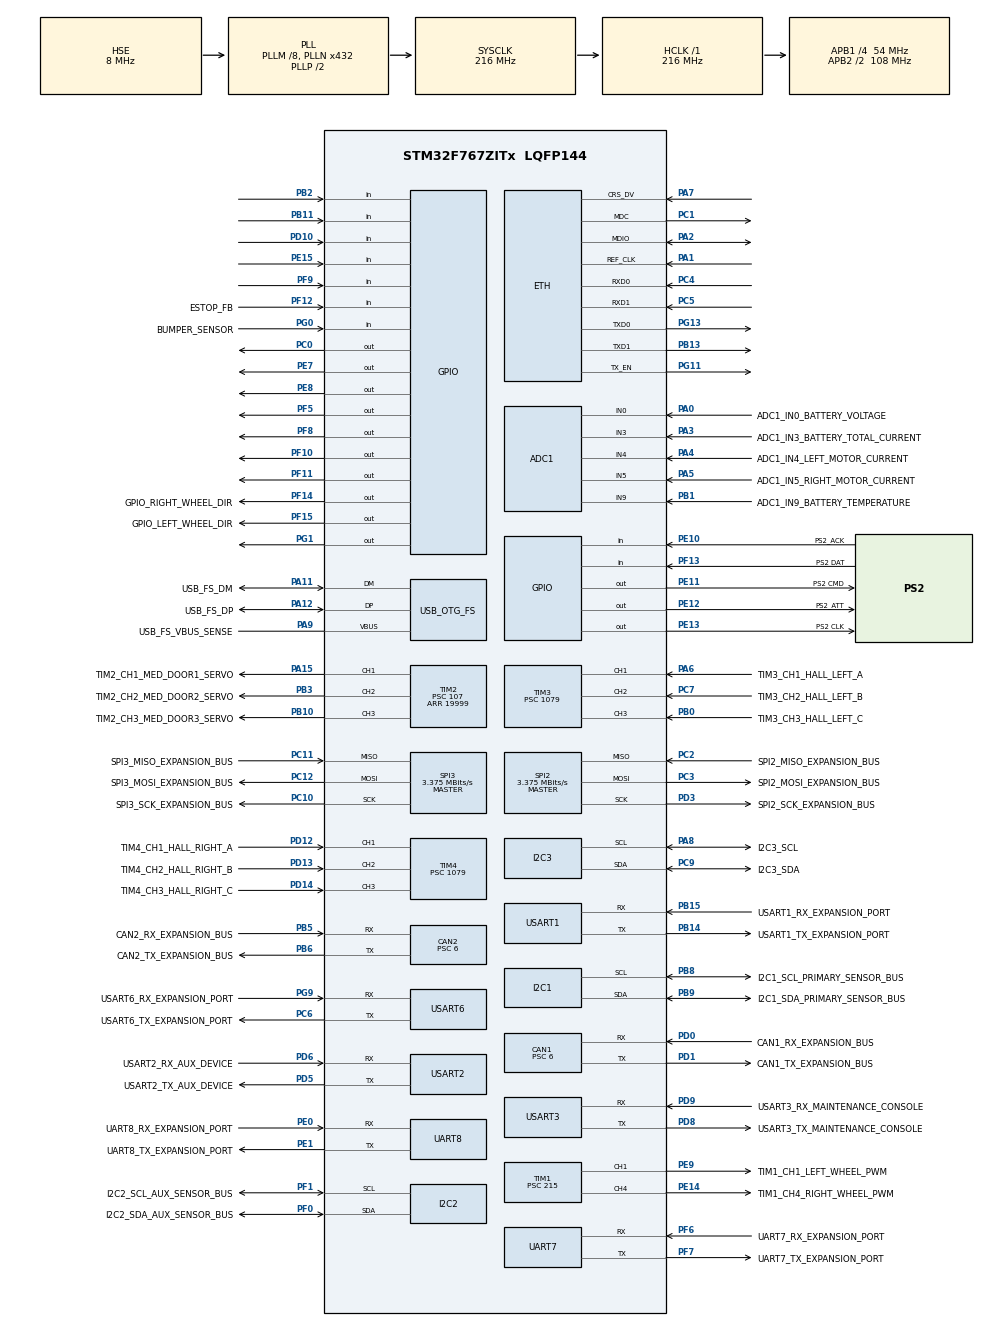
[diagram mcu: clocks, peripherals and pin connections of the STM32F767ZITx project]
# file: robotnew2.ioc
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ADC1.Channel-0\#ChannelRegularConversion=ADC_CHANNEL_0
ADC1.Channel-1\#ChannelRegularConversion=ADC_CHANNEL_3
ADC1.Channel-2\#ChannelRegularConversion=ADC_CHANNEL_4
ADC1.Channel-3\#ChannelRegularConversion=ADC_CHANNEL_5
ADC1.Channel-4\#ChannelRegularConversion=ADC_CHANNEL_9
ADC1.ContinuousConvMode=ENABLE
ADC1.DMAContinuousRequests=ENABLE
ADC1.NbrOfConversion=5
ADC1.NbrOfConversionFlag=1
ADC1.Rank-0\#ChannelRegularConversion=1
ADC1.Rank-1\#ChannelRegularConversion=2
ADC1.Rank-2\#ChannelRegularConversion=3
ADC1.Rank-3\#ChannelRegularConversion=4
ADC1.Rank-4\#ChannelRegularConversion=5
ADC1.SamplingTime-0\#ChannelRegularConversion=ADC_SAMPLETIME_480CYCLES
ADC1.SamplingTime-1\#ChannelRegularConversion=ADC_SAMPLETIME_480CYCLES
ADC1.SamplingTime-2\#ChannelRegularConversion=ADC_SAMPLETIME_480CYCLES
ADC1.SamplingTime-3\#ChannelRegularConversion=ADC_SAMPLETIME_480CYCLES
ADC1.SamplingTime-4\#ChannelRegularConversion=ADC_SAMPLETIME_480CYCLES
ADC1.ScanConvMode=ADC_SCAN_ENABLE
ADC1.master=1
CAN1.BS1=CAN_BS1_15TQ
CAN1.BS2=CAN_BS2_2TQ
CAN1.CalculateBaudRate=500000
CAN1.CalculateTimeBit=2000
CAN1.CalculateTimeQuantum=111.11111111111111
CAN1.NART=ENABLE
CAN1.Prescaler=6
CAN2.BS1=CAN_BS1_15TQ
CAN2.BS2=CAN_BS2_2TQ
CAN2.CalculateBaudRate=500000
CAN2.CalculateTimeBit=2000
CAN2.CalculateTimeQuantum=111.11111111111111
CAN2.Prescaler=6
CORTEX_M7.CPU_ICache=Enabled
CORTEX_M7.Enable-Cortex_Memory_Protection_Unit_Region0_Settings=__NULL
CORTEX_M7.MPU_Control=__NULL
CORTEX_M7.default_mode_Activation=0
Dma.ADC1.0.Direction=DMA_PERIPH_TO_MEMORY
Dma.ADC1.0.FIFOMode=DMA_FIFOMODE_DISABLE
Dma.ADC1.0.Instance=DMA2_Stream0
Dma.ADC1.0.MemDataAlignment=DMA_MDATAALIGN_HALFWORD
Dma.ADC1.0.MemInc=DMA_MINC_ENABLE
Dma.ADC1.0.Mode=DMA_CIRCULAR
Dma.ADC1.0.PeriphDataAlignment=DMA_PDATAALIGN_HALFWORD
Dma.ADC1.0.PeriphInc=DMA_PINC_DISABLE
Dma.ADC1.0.Priority=DMA_PRIORITY_LOW
Dma.Request0=ADC1
ETH.MediaInterface=HAL_ETH_RMII_MODE
FREERTOS.Tasks01=defaultTask,0,256,StartDefaultTask,Default,NULL,Dynamic,NULL,NULL
FREERTOS.configTOTAL_HEAP_SIZE=81920
FREERTOS.configUSE_NEWLIB_REENTRANT=1
I2C1.Timing=0x20404768
I2C2.Timing=0x20404768
I2C3.Timing=0x20404768
LWIP.BSP.number=1
LWIP.IP_ADDRESS=192.168.001.067
LWIP.LWIP_DHCP=0
LWIP.MEMP_NUM_UDP_PCB=15
LWIP.MEM_SIZE=10240
LWIP.NETMASK_ADDRESS=255.255.255.000
LWIP.PBUF_POOL_BUFSIZE=1536
LWIP.Version=v2.1.2_Cube
LWIP0.BSP.STBoard=false
LWIP0.BSP.api=BSP_COMPONENT_DRIVER
LWIP0.BSP.component=LAN8742
LWIP0.BSP.instance=LAN8742
LWIP0.BSP.name=Driver_PHY
LWIP0.BSP.semaphore=S_LAN8742
LWIP0.BSP.solution=LAN8742
Mcu.Family=STM32F7
Mcu.Name=STM32F767ZITx
Mcu.Package=LQFP144
NVIC.CAN1_RX0_IRQn=true\:5\:0\:true\:false\:true\:false\:true\:true\:true
NVIC.CAN1_SCE_IRQn=true\:5\:0\:true\:false\:true\:false\:true\:true\:true
NVIC.CAN1_TX_IRQn=true\:5\:0\:true\:false\:true\:false\:true\:true\:true
NVIC.CAN2_RX0_IRQn=true\:5\:0\:true\:false\:true\:false\:true\:true\:true
NVIC.CAN2_SCE_IRQn=true\:5\:0\:true\:false\:true\:false\:true\:true\:true
NVIC.CAN2_TX_IRQn=true\:5\:0\:true\:false\:true\:false\:true\:true\:true
NVIC.DMA2_Stream0_IRQn=true\:5\:0\:true\:false\:true\:false\:false\:true\:true
NVIC.ETH_IRQn=true\:5\:0\:false\:false\:true\:true\:false\:true\:true
NVIC.I2C1_ER_IRQn=true\:5\:0\:true\:false\:true\:false\:true\:true\:true
NVIC.I2C1_EV_IRQn=true\:5\:0\:true\:false\:true\:false\:true\:true\:true
NVIC.I2C2_ER_IRQn=true\:5\:0\:true\:false\:true\:false\:true\:true\:true
NVIC.I2C2_EV_IRQn=true\:5\:0\:true\:false\:true\:false\:true\:true\:true
NVIC.I2C3_ER_IRQn=true\:5\:0\:true\:false\:true\:false\:true\:true\:true
NVIC.I2C3_EV_IRQn=true\:5\:0\:true\:false\:true\:false\:true\:true\:true
NVIC.OTG_FS_IRQn=true\:5\:0\:false\:false\:true\:true\:false\:true\:true
NVIC.PriorityGroup=NVIC_PRIORITYGROUP_4
NVIC.SPI2_IRQn=true\:5\:0\:true\:false\:true\:false\:true\:true\:true
NVIC.SPI3_IRQn=true\:5\:0\:true\:false\:true\:false\:true\:true\:true
NVIC.TIM3_IRQn=true\:5\:0\:true\:false\:true\:false\:true\:true\:true
NVIC.TIM4_IRQn=true\:5\:0\:true\:false\:true\:false\:true\:true\:true
NVIC.TIM6_DAC_IRQn=true\:15\:0\:false\:false\:true\:false\:false\:true\:true
NVIC.TimeBase=TIM6_DAC_IRQn
NVIC.TimeBaseIP=TIM6
NVIC.UART7_IRQn=true\:5\:0\:false\:false\:true\:true\:true\:true\:true
NVIC.UART8_IRQn=true\:5\:0\:false\:false\:true\:true\:true\:true\:true
NVIC.USART1_IRQn=true\:5\:0\:false\:false\:true\:true\:true\:true\:true
NVIC.USART2_IRQn=true\:5\:0\:true\:false\:true\:false\:true\:true\:true
NVIC.USART3_IRQn=true\:5\:0\:true\:false\:true\:false\:true\:true\:true
NVIC.USART6_IRQn=true\:5\:0\:true\:false\:true\:false\:true\:true\:true
PA0/WKUP.GPIO_Label=ADC1_IN0_BATTERY_VOLTAGE
PA0/WKUP.Signal=ADCx_IN0
PA1.Mode=RMII
PA1.Signal=ETH_REF_CLK
PA11.GPIO_Label=USB_FS_DM
PA11.Mode=Device_Only
PA11.Signal=USB_OTG_FS_DM
PA12.GPIO_Label=USB_FS_DP
PA12.Mode=Device_Only
PA12.Signal=USB_OTG_FS_DP
PA13.Mode=Serial_Wire
PA13.Signal=SYS_JTMS-SWDIO
PA14.Mode=Serial_Wire
PA14.Signal=SYS_JTCK-SWCLK
PA15.GPIO_Label=TIM2_CH1_MED_DOOR1_SERVO
PA15.Signal=S_TIM2_CH1_ETR
PA2.Mode=RMII
PA2.Signal=ETH_MDIO
PA3.GPIO_Label=ADC1_IN3_BATTERY_TOTAL_CURRENT
PA3.Signal=ADCx_IN3
PA4.GPIO_Label=ADC1_IN4_LEFT_MOTOR_CURRENT
PA4.Signal=ADCx_IN4
PA5.GPIO_Label=ADC1_IN5_RIGHT_MOTOR_CURRENT
PA5.Signal=ADCx_IN5
PA6.GPIO_Label=TIM3_CH1_HALL_LEFT_A
PA6.Signal=S_TIM3_CH1
PA7.Mode=RMII
PA7.Signal=ETH_CRS_DV
PA8.GPIO_Label=I2C3_SCL
PA8.GPIO_Mode=GPIO_MODE_AF_OD
PA8.GPIO_Pu=GPIO_NOPULL
PA8.GPIO_Speed=GPIO_SPEED_FREQ_VERY_HIGH
PA8.Mode=I2C
PA8.Signal=I2C3_SCL
PA9.GPIO_Label=USB_FS_VBUS_SENSE
PA9.Mode=Activate_VBUS
PA9.Signal=USB_OTG_FS_VBUS
PB0.GPIO_Label=TIM3_CH3_HALL_LEFT_C
PB0.Signal=S_TIM3_CH3
PB1.GPIO_Label=ADC1_IN9_BATTERY_TEMPERATURE
PB1.Signal=ADCx_IN9
PB10.GPIO_Label=TIM2_CH3_MED_DOOR3_SERVO
PB10.Signal=S_TIM2_CH3
PB11.Signal=GPIO_Input
PB13.Mode=RMII
PB13.Signal=ETH_TXD1
PB14.GPIO_Label=USART1_TX_EXPANSION_PORT
PB14.Mode=Asynchronous
PB14.Signal=USART1_TX
PB15.GPIO_Label=USART1_RX_EXPANSION_PORT
PB15.Mode=Asynchronous
PB15.Signal=USART1_RX
PB2.Signal=GPIO_Input
PB3.GPIO_Label=TIM2_CH2_MED_DOOR2_SERVO
PB3.Signal=S_TIM2_CH2
PB5.GPIO_Label=CAN2_RX_EXPANSION_BUS
PB5.Mode=CAN_Activate
PB5.Signal=CAN2_RX
PB6.GPIO_Label=CAN2_TX_EXPANSION_BUS
PB6.Mode=CAN_Activate
PB6.Signal=CAN2_TX
PB8.GPIO_Label=I2C1_SCL_PRIMARY_SENSOR_BUS
PB8.Mode=I2C
PB8.Signal=I2C1_SCL
PB9.GPIO_Label=I2C1_SDA_PRIMARY_SENSOR_BUS
PB9.Mode=I2C
PB9.Signal=I2C1_SDA
PC0.Signal=GPIO_Output
PC1.Mode=RMII
PC1.Signal=ETH_MDC
PC10.GPIO_Label=SPI3_SCK_EXPANSION_BUS
PC10.Mode=Full_Duplex_Master
PC10.Signal=SPI3_SCK
PC11.GPIO_Label=SPI3_MISO_EXPANSION_BUS
PC11.Mode=Full_Duplex_Master
PC11.Signal=SPI3_MISO
PC12.GPIO_Label=SPI3_MOSI_EXPANSION_BUS
PC12.Mode=Full_Duplex_Master
PC12.Signal=SPI3_MOSI
PC14/OSC32_IN.Mode=LSE-External-Oscillator
PC14/OSC32_IN.Signal=RCC_OSC32_IN
PC15/OSC32_OUT.Mode=LSE-External-Oscillator
PC15/OSC32_OUT.Signal=RCC_OSC32_OUT
PC2.GPIO_Label=SPI2_MISO_EXPANSION_BUS
PC2.Mode=Full_Duplex_Master
PC2.Signal=SPI2_MISO
PC3.GPIO_Label=SPI2_MOSI_EXPANSION_BUS
PC3.Mode=Full_Duplex_Master
PC3.Signal=SPI2_MOSI
PC4.Mode=RMII
PC4.Signal=ETH_RXD0
PC5.Mode=RMII
PC5.Signal=ETH_RXD1
PC6.GPIO_Label=USART6_TX_EXPANSION_PORT
PC6.Mode=Asynchronous
PC6.Signal=USART6_TX
PC7.GPIO_Label=TIM3_CH2_HALL_LEFT_B
PC7.Signal=S_TIM3_CH2
PC9.GPIO_Label=I2C3_SDA
PC9.GPIO_Mode=GPIO_MODE_AF_OD
PC9.GPIO_Pu=GPIO_NOPULL
PC9.GPIO_Speed=GPIO_SPEED_FREQ_VERY_HIGH
PC9.Mode=I2C
PC9.Signal=I2C3_SDA
PD0.GPIO_Label=CAN1_RX_EXPANSION_BUS
PD0.Mode=CAN_Activate
PD0.Signal=CAN1_RX
PD1.GPIO_Label=CAN1_TX_EXPANSION_BUS
PD1.Mode=CAN_Activate
PD1.Signal=CAN1_TX
PD10.Signal=GPIO_Input
PD12.GPIO_Label=TIM4_CH1_HALL_RIGHT_A
PD12.Signal=S_TIM4_CH1
PD13.GPIO_Label=TIM4_CH2_HALL_RIGHT_B
PD13.Signal=S_TIM4_CH2
PD14.GPIO_Label=TIM4_CH3_HALL_RIGHT_C
PD14.Signal=S_TIM4_CH3
PD3.GPIO_Label=SPI2_SCK_EXPANSION_BUS
PD3.Mode=Full_Duplex_Master
PD3.Signal=SPI2_SCK
PD5.GPIO_Label=USART2_TX_AUX_DEVICE
PD5.Mode=Asynchronous
PD5.Signal=USART2_TX
PD6.GPIO_Label=USART2_RX_AUX_DEVICE
PD6.Mode=Asynchronous
PD6.Signal=USART2_RX
PD8.GPIO_Label=USART3_TX_MAINTENANCE_CONSOLE
PD8.Mode=Asynchronous
PD8.Signal=USART3_TX
PD9.GPIO_Label=USART3_RX_MAINTENANCE_CONSOLE
PD9.Mode=Asynchronous
PD9.Signal=USART3_RX
PE0.GPIO_Label=UART8_RX_EXPANSION_PORT
PE0.Mode=Asynchronous
PE0.Signal=UART8_RX
PE1.GPIO_Label=UART8_TX_EXPANSION_PORT
PE1.Mode=Asynchronous
PE1.Signal=UART8_TX
PE10.GPIO_Label=PS2_ACK
PE10.GPIO_PuPd=GPIO_PULLUP
PE10.Signal=GPIO_Input
PE11.GPIO_Label=PS2 CMD
PE11.PinState=GPIO_PIN_SET
PE11.Signal=GPIO_Output
PE12.GPIO_Label=PS2_ATT
PE12.GPIO_Speed=GPIO_SPEED_FREQ_LOW
PE12.PinState=GPIO_PIN_SET
PE12.Signal=GPIO_Output
PE13.GPIO_Label=PS2 CLK
PE13.PinState=GPIO_PIN_SET
PE13.Signal=GPIO_Output
PE14.GPIO_Label=TIM1_CH4_RIGHT_WHEEL_PWM
PE14.Signal=S_TIM1_CH4
PE15.Signal=GPIO_Input
PE7.Signal=GPIO_Output
PE8.Signal=GPIO_Output
PE9.GPIO_Label=TIM1_CH1_LEFT_WHEEL_PWM
PE9.Signal=S_TIM1_CH1
PF0.GPIO_Label=I2C2_SDA_AUX_SENSOR_BUS
PF0.Mode=I2C
PF0.Signal=I2C2_SDA
PF1.GPIO_Label=I2C2_SCL_AUX_SENSOR_BUS
PF1.Mode=I2C
PF1.Signal=I2C2_SCL
PF10.Signal=GPIO_Output
PF11.Signal=GPIO_Output
PF12.GPIO_Label=ESTOP_FB
PF12.GPIO_PuPd=GPIO_PULLUP
PF12.Signal=GPIO_Input
PF13.GPIO_Label=PS2 DAT
PF13.GPIO_PuPd=GPIO_PULLUP
PF13.Signal=GPIO_Input
PF14.GPIO_Label=GPIO_RIGHT_WHEEL_DIR
PF14.GPIO_Speed=GPIO_SPEED_FREQ_MEDIUM
PF14.PinState=GPIO_PIN_SET
PF14.Signal=GPIO_Output
PF15.GPIO_Label=GPIO_LEFT_WHEEL_DIR
PF15.GPIO_Speed=GPIO_SPEED_FREQ_MEDIUM
PF15.PinState=GPIO_PIN_SET
PF15.Signal=GPIO_Output
PF5.Signal=GPIO_Output
PF6.GPIO_Label=UART7_RX_EXPANSION_PORT
PF6.Mode=Asynchronous
PF6.Signal=UART7_RX
PF7.GPIO_Label=UART7_TX_EXPANSION_PORT
PF7.Mode=Asynchronous
PF7.Signal=UART7_TX
PF8.Signal=GPIO_Output
PF9.Signal=GPIO_Input
PG0.GPIO_Label=BUMPER_SENSOR
PG0.Signal=GPIO_Input
PG1.Signal=GPIO_Output
PG11.Mode=RMII
PG11.Signal=ETH_TX_EN
PG13.Mode=RMII
PG13.Signal=ETH_TXD0
PG9.GPIO_Label=USART6_RX_EXPANSION_PORT
PG9.Mode=Asynchronous
PG9.Signal=USART6_RX
PH0/OSC_IN.Mode=HSE-External-Clock-Source
PH0/OSC_IN.Signal=RCC_OSC_IN
PH1/OSC_OUT.Mode=HSE-External-Clock-Source
PH1/OSC_OUT.Signal=RCC_OSC_OUT
ProjectManager.HeapSize=0x200
ProjectManager.StackSize=0x400
ProjectManager.TargetToolchain=STM32CubeIDE
RCC.AHBFreq_Value=216000000
RCC.APB1CLKDivider=RCC_HCLK_DIV4
RCC.APB1Freq_Value=54000000
RCC.APB1TimFreq_Value=108000000
RCC.APB2CLKDivider=RCC_HCLK_DIV2
RCC.APB2Freq_Value=108000000
RCC.APB2TimFreq_Value=216000000
RCC.CortexFreq_Value=216000000
RCC.HCLKFreq_Value=216000000
RCC.HSE_Timout=3000
RCC.HSE_VALUE=8000000
RCC.HSI_VALUE=16000000
RCC.PLLM=8
RCC.PLLN=432
RCC.PLLQ=9
RCC.RCC_TIM_PRescaler_Selection=RCC_TIMPRES_DESACTIVATED
RCC.RTCClockSelection=RCC_RTCCLKSOURCE_LSE
RCC.SYSCLKFreq_VALUE=216000000
RCC.SYSCLKSource=RCC_SYSCLKSOURCE_PLLCLK
RCC.USBFreq_Value=48000000
RCC.VCOOutputFreq_Value=432000000
SH.ADCx_IN0.0=ADC1_IN0,IN0
SH.ADCx_IN3.0=ADC1_IN3,IN3
SH.ADCx_IN4.0=ADC1_IN4,IN4
SH.ADCx_IN5.0=ADC1_IN5,IN5
SH.ADCx_IN9.0=ADC1_IN9,IN9
SH.S_TIM1_CH1.0=TIM1_CH1,PWM Generation1 CH1
SH.S_TIM1_CH4.0=TIM1_CH4,PWM Generation4 CH4
SH.S_TIM2_CH1_ETR.0=TIM2_CH1,PWM Generation1 CH1
SH.S_TIM2_CH2.0=TIM2_CH2,PWM Generation2 CH2
SH.S_TIM2_CH3.0=TIM2_CH3,PWM Generation3 CH3
SH.S_TIM3_CH1.0=TIM3_CH1,Xored_Inputs_Hall_Sensor_Interface
SH.S_TIM3_CH2.0=TIM3_CH2,Xored_Inputs_Hall_Sensor_Interface
SH.S_TIM3_CH3.0=TIM3_CH3,Xored_Inputs_Hall_Sensor_Interface
SH.S_TIM4_CH1.0=TIM4_CH1,Xored_Inputs_Hall_Sensor_Interface
SH.S_TIM4_CH2.0=TIM4_CH2,Xored_Inputs_Hall_Sensor_Interface
SH.S_TIM4_CH3.0=TIM4_CH3,Xored_Inputs_Hall_Sensor_Interface
SPI2.BaudRatePrescaler=SPI_BAUDRATEPRESCALER_16
SPI2.CalculateBaudRate=3.375 MBits/s
SPI2.DataSize=SPI_DATASIZE_8BIT
SPI2.Direction=SPI_DIRECTION_2LINES
SPI2.Mode=SPI_MODE_MASTER
SPI2.VirtualType=VM_MASTER
SPI3.BaudRatePrescaler=SPI_BAUDRATEPRESCALER_16
SPI3.CalculateBaudRate=3.375 MBits/s
SPI3.DataSize=SPI_DATASIZE_8BIT
SPI3.Direction=SPI_DIRECTION_2LINES
SPI3.Mode=SPI_MODE_MASTER
SPI3.NSSPMode=SPI_NSS_PULSE_DISABLE
SPI3.VirtualType=VM_MASTER
TIM1.Channel-PWM\ Generation1\ CH1=TIM_CHANNEL_1
TIM1.Channel-PWM\ Generation4\ CH4=TIM_CHANNEL_4
TIM1.Period=99
TIM1.Prescaler=215
TIM2.Channel-PWM\ Generation1\ CH1=TIM_CHANNEL_1
TIM2.Channel-PWM\ Generation2\ CH2=TIM_CHANNEL_2
TIM2.Channel-PWM\ Generation3\ CH3=TIM_CHANNEL_3
TIM2.Period=19999
TIM2.Prescaler=107
TIM3.Prescaler=1079
TIM4.Prescaler=1079
TIM5.Prescaler=107
USART1.VirtualMode-Asynchronous=VM_ASYNC
USART2.VirtualMode-Asynchronous=VM_ASYNC
USART3.VirtualMode-Asynchronous=VM_ASYNC
USART6.VirtualMode-Asynchronous=VM_ASYNC
USB_DEVICE.CLASS_NAME_FS=CDC
USB_DEVICE.VirtualMode-CDC_FS=Cdc
USB_DEVICE.VirtualModeFS=Cdc_FS
USB_OTG_FS.VirtualMode=Device_Only
VP_FREERTOS_VS_CMSIS_V1.Mode=CMSIS_V1
VP_LWIP_VS_Enabled.Mode=Enabled
VP_RTC_VS_RTC_Activate.Mode=RTC_Enabled
VP_RTC_VS_RTC_Calendar.Mode=RTC_Calendar
VP_SYS_VS_tim6.Mode=TIM6
VP_TIM1_VS_ClockSourceINT.Mode=Internal
VP_TIM2_VS_ClockSourceINT.Mode=Internal
VP_TIM3_VS_ClockSourceINT.Mode=Internal
VP_TIM4_VS_ClockSourceINT.Mode=Internal
VP_TIM5_VS_ClockSourceINT.Mode=Internal
VP_USB_DEVICE_VS_USB_DEVICE_CDC_FS.Mode=CDC_FS
board=custom

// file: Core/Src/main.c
/* USER CODE BEGIN Header */
/**
  ******************************************************************************
  * @file           : main.c
  * @brief          : Main program body
  ******************************************************************************
  * @attention
  *
  * Copyright (c) 2026 STMicroelectronics.
  * All rights reserved.
  *
  * This software is licensed under terms that can be found in the LICENSE file
  * in the root directory of this software component.
  * If no LICENSE file comes with this software, it is provided AS-IS.
  *
  ******************************************************************************
  */
/* USER CODE END Header */
#include "main.h"
#include "cmsis_os.h"
#include "adc.h"
#include "can.h"
#include "dma.h"
#include "i2c.h"
#include "lwip.h"
#include "rtc.h"
#include "spi.h"
#include "tim.h"
#include "usart.h"
#include "usb_device.h"
#include "gpio.h"

/* USER CODE BEGIN PD */
/* ===== MOTOR CONFIGURATION ===== */

#define MOTOR_PWM_MAX_PERCENT              70
#define MOTOR_STEER_REDUCTION_MAX_PERCENT  70U
#define MOTOR_RAMP_STEP_PERCENT             2

#define JOYSTICK_DEADZONE_COUNTS           13

/* Dao chieu joystick neu can */
#define JOYSTICK_X_INVERT                  0U
#define JOYSTICK_Y_INVERT                  1U

/* Dao chieu DIR rieng tung banh */
#define MOTOR_LEFT_DIR_INVERT              1U
#define MOTOR_RIGHT_DIR_INVERT             0U

/* Muc DIR mac dinh de chay tien */
#define MOTOR_FORWARD_LEVEL                GPIO_PIN_SET

/* USER CODE END PD */

/* USER CODE BEGIN PV */
static int16_t s_motor_left_applied = 0;
static int16_t s_motor_right_applied = 0;

/* Bat buoc tha L1 roi moi duoc chay */
static uint8_t s_motor_armed = 0U;

/* Theo doi khi Debug */
volatile int16_t g_motor_left_target = 0;
volatile int16_t g_motor_right_target = 0;
volatile int16_t g_motor_left_applied = 0;
volatile int16_t g_motor_right_applied = 0;

/* USER CODE END PV */

void SystemClock_Config(void);
void MX_FREERTOS_Init(void);
/* USER CODE BEGIN PFP */
void Robot_MotorControl_Update(
    uint8_t ps2_connected,
    uint8_t lx,
    uint8_t ly,
    uint8_t l1_pressed
);
/* USER CODE END PFP */

/* USER CODE BEGIN 0 */
/* =====================================================
 * MOTOR CONTROL - STM32F767ZI
 * PWM: TIM1_CH1 - Left wheel
 * PWM: TIM1_CH4 - Right wheel
 * DIR: PF15 - Left wheel
 * DIR: PF14 - Right wheel
 * ===================================================== */

static int16_t Motor_Abs16(int16_t value)
{
    return (value < 0) ? -value : value;
}

/* Convert joystick raw value to -100 ... +100 */
static int16_t Joystick_ToPercent(
    uint8_t raw,
    uint8_t invert
)
{
    int16_t delta = (int16_t)raw - 128;
    int16_t deadzone = JOYSTICK_DEADZONE_COUNTS;

    if (invert != 0U)
    {
        delta = -delta;
    }

    if (delta > deadzone)
    {
        return (int16_t)(
            ((delta - deadzone) * 100) / (127 - deadzone)
        );
    }

    if (delta < -deadzone)
    {
        return (int16_t)(
            -(((-delta - deadzone) * 100) / (128 - deadzone))
        );
    }

    return 0;
}

/* Smooth acceleration and deceleration */
static int16_t Motor_RampToward(
    int16_t current,
    int16_t target
)
{
    /* Khong doi chieu truc tiep khi banh dang quay */
    if (((current > 0) && (target < 0)) ||
        ((current < 0) && (target > 0)))
    {
        target = 0;
    }

    if (current < target)
    {
        current += MOTOR_RAMP_STEP_PERCENT;

        if (current > target)
            current = target;
    }
    else if (current > target)
    {
        current -= MOTOR_RAMP_STEP_PERCENT;

        if (current < target)
            current = target;
    }

    return current;
}

/* Apply DIR and PWM to one wheel */
static void Motor_WriteOne(
    uint16_t dir_pin,
    uint8_t dir_invert,
    uint32_t pwm_channel,
    int16_t command
)
{
    uint8_t forward_requested;
    GPIO_PinState dir_level;
    GPIO_PinState reverse_level;

    uint32_t duty;
    uint32_t period_counts;
    uint32_t compare;

    forward_requested = (command >= 0) ? 1U : 0U;

    if (dir_invert != 0U)
    {
        forward_requested ^= 1U;
    }

    reverse_level = (MOTOR_FORWARD_LEVEL == GPIO_PIN_SET)
                  ? GPIO_PIN_RESET
                  : GPIO_PIN_SET;

    dir_level = (forward_requested != 0U)
              ? MOTOR_FORWARD_LEVEL
              : reverse_level;

    HAL_GPIO_WritePin(GPIOF, dir_pin, dir_level);

    duty = (uint32_t)Motor_Abs16(command);

    if (duty > MOTOR_PWM_MAX_PERCENT)
    {
        duty = MOTOR_PWM_MAX_PERCENT;
    }

    period_counts = __HAL_TIM_GET_AUTORELOAD(&htim1) + 1U;

    compare = (period_counts * duty) / 100U;

    __HAL_TIM_SET_COMPARE(
        &htim1,
        pwm_channel,
        compare
    );
}

/* Apply both wheels */
/* Apply both wheels */
static void Motor_WriteOutputs(
    int16_t left,
    int16_t right
)
{
    Motor_WriteOne(
        GPIO_LEFT_WHEEL_DIR_Pin,
        MOTOR_LEFT_DIR_INVERT,
        TIM_CHANNEL_1,
        left
    );

    Motor_WriteOne(
        GPIO_RIGHT_WHEEL_DIR_Pin,
        MOTOR_RIGHT_DIR_INVERT,
        TIM_CHANNEL_4,
        right
    );
}

/* Immediate stop - bypass acceleration ramp */
static void Motor_StopImmediate(void)
{
    s_motor_left_applied = 0;
    s_motor_right_applied = 0;

    g_motor_left_target = 0;
    g_motor_right_target = 0;

    g_motor_left_applied = 0;
    g_motor_right_applied = 0;

    Motor_WriteOutputs(0, 0);
}

/* =====================================================
 * MAIN ROBOT MOTOR CONTROL FUNCTION
 *
 * Y: Forward / Reverse
 * X: Steering
 * L1: Dead-man enable
 * ===================================================== */

void Robot_MotorControl_Update(
    uint8_t ps2_connected,
    uint8_t lx,
    uint8_t ly,
    uint8_t l1_pressed
)
{
    int16_t linear;
    int16_t steering;

    int16_t base_speed;
    int16_t reduction;
    int16_t inner_speed;

    int16_t left_target = 0;
    int16_t right_target = 0;

    /* 1. Mat ket noi: dung ngay */
    if (ps2_connected == 0U)
    {
        s_motor_armed = 0U;
        Motor_StopImmediate();
        return;
    }

    /* 2. Tha L1: dung ngay va cho phep nhan lai */
    if (l1_pressed == 0U)
    {
        s_motor_armed = 1U;
        Motor_StopImmediate();
        return;
    }

    /* 3. Chua tha L1 sau khi khoi dong/mat ket noi */
    if (s_motor_armed == 0U)
    {
        Motor_StopImmediate();
        return;
    }

    /* 4. Doc joystick */
    linear = Joystick_ToPercent(
        ly,
        JOYSTICK_Y_INVERT
    );

    steering = Joystick_ToPercent(
        lx,
        JOYSTICK_X_INVERT
    );

    base_speed = Motor_Abs16(linear);

    /* 5. Chi re khi co lenh tien/lui */
    if (linear != 0)
    {
        reduction = (int16_t)(
            (Motor_Abs16(steering) *
             MOTOR_STEER_REDUCTION_MAX_PERCENT) / 100U
        );

        inner_speed = (int16_t)(
            (base_speed * (100 - reduction)) / 100
        );

        if (linear > 0)
        {
            /* Dang tien */
            if (steering > 0)
            {
                /* Re phai: banh phai cham hon */
                left_target = base_speed;
                right_target = inner_speed;
            }
            else if (steering < 0)
            {
                /* Re trai: banh trai cham hon */
                left_target = inner_speed;
                right_target = base_speed;
            }
            else
            {
                left_target = base_speed;
                right_target = base_speed;
            }
        }
        else
        {
            /* Dang lui: doi banh trong de giu huong mui robot */
            if (steering > 0)
            {
                left_target = -inner_speed;
                right_target = -base_speed;
            }
            else if (steering < 0)
            {
                left_target = -base_speed;
                right_target = -inner_speed;
            }
            else
            {
                left_target = -base_speed;
                right_target = -base_speed;
            }
        }
    }

    /* 6. Gioi han PWM toi da 70% */
    left_target = (int16_t)(
        (left_target * MOTOR_PWM_MAX_PERCENT) / 100
    );

    right_target = (int16_t)(
        (right_target * MOTOR_PWM_MAX_PERCENT) / 100
    );

    g_motor_left_target = left_target;
    g_motor_right_target = right_target;

    /* 7. Tang giam toc binh thuong */
    s_motor_left_applied = Motor_RampToward(
        s_motor_left_applied,
        left_target
    );

    s_motor_right_applied = Motor_RampToward(
        s_motor_right_applied,
        right_target
    );

    g_motor_left_applied = s_motor_left_applied;
    g_motor_right_applied = s_motor_right_applied;

    /* 8. Xuat DIR va PWM */
    Motor_WriteOutputs(
        s_motor_left_applied,
        s_motor_right_applied
    );
}
/* USER CODE END 0 */

int main(void)
{

  /* Enable the CPU Cache */

  /* Enable I-Cache---------------------------------------------------------*/
  SCB_EnableICache();

  /* MCU Configuration--------------------------------------------------------*/

  /* Reset of all peripherals, Initializes the Flash interface and the Systick. */
  HAL_Init();

  /* Configure the system clock */
  SystemClock_Config();

  /* Initialize all configured peripherals */
  MX_GPIO_Init();
  MX_DMA_Init();
  MX_RTC_Init();
  MX_ADC1_Init();
  MX_CAN1_Init();
  MX_I2C1_Init();
  MX_SPI3_Init();
  MX_USART3_UART_Init();
  MX_USART6_UART_Init();
  MX_TIM1_Init();
  MX_TIM2_Init();
  MX_TIM3_Init();
  MX_TIM4_Init();
  MX_CAN2_Init();
  MX_I2C2_Init();
  MX_I2C3_Init();
  MX_SPI2_Init();
  MX_UART7_Init();
  MX_UART8_Init();
  MX_USART2_UART_Init();
  MX_USART1_UART_Init();
  MX_TIM5_Init();
  /* USER CODE BEGIN 2 */
  /* Start PWM for two BLDC controllers */

  __HAL_TIM_SET_COMPARE(&htim1, TIM_CHANNEL_1, 0U);
  __HAL_TIM_SET_COMPARE(&htim1, TIM_CHANNEL_4, 0U);

  if (HAL_TIM_PWM_Start(&htim1, TIM_CHANNEL_1) != HAL_OK)
  {
      Error_Handler();
  }

  if (HAL_TIM_PWM_Start(&htim1, TIM_CHANNEL_4) != HAL_OK)
  {
      Error_Handler();
  }
  /* USER CODE END 2 */

  /* Call init function for freertos objects (in cmsis_os2.c) */
  MX_FREERTOS_Init();

  /* Start scheduler */
  osKernelStart();

  /* We should never get here as control is now taken by the scheduler */

  /* Infinite loop */
  while (1)
  {

  }
}

void SystemClock_Config(void)
{
  RCC_OscInitTypeDef RCC_OscInitStruct = {0};
  RCC_ClkInitTypeDef RCC_ClkInitStruct = {0};

  /** Configure LSE Drive Capability
  */
  HAL_PWR_EnableBkUpAccess();
  __HAL_RCC_LSEDRIVE_CONFIG(RCC_LSEDRIVE_LOW);

  /** Configure the main internal regulator output voltage
  */
  __HAL_RCC_PWR_CLK_ENABLE();
  __HAL_PWR_VOLTAGESCALING_CONFIG(PWR_REGULATOR_VOLTAGE_SCALE1);

  /** Initializes the RCC Oscillators according to the specified parameters
  * in the RCC_OscInitTypeDef structure.
  */
  RCC_OscInitStruct.OscillatorType = RCC_OSCILLATORTYPE_HSE|RCC_OSCILLATORTYPE_LSE;
  RCC_OscInitStruct.HSEState = RCC_HSE_BYPASS;
  RCC_OscInitStruct.LSEState = RCC_LSE_ON;
  RCC_OscInitStruct.PLL.PLLState = RCC_PLL_ON;
  RCC_OscInitStruct.PLL.PLLSource = RCC_PLLSOURCE_HSE;
  RCC_OscInitStruct.PLL.PLLM = 8;
  RCC_OscInitStruct.PLL.PLLN = 432;
  RCC_OscInitStruct.PLL.PLLP = RCC_PLLP_DIV2;
  RCC_OscInitStruct.PLL.PLLQ = 9;
  RCC_OscInitStruct.PLL.PLLR = 2;
  if (HAL_RCC_OscConfig(&RCC_OscInitStruct) != HAL_OK)
  {
    Error_Handler();
  }

  /** Activate the Over-Drive mode
  */
  if (HAL_PWREx_EnableOverDrive() != HAL_OK)
  {
    Error_Handler();
  }

  /** Initializes the CPU, AHB and APB buses clocks
  */
  RCC_ClkInitStruct.ClockType = RCC_CLOCKTYPE_HCLK|RCC_CLOCKTYPE_SYSCLK
                              |RCC_CLOCKTYPE_PCLK1|RCC_CLOCKTYPE_PCLK2;
  RCC_ClkInitStruct.SYSCLKSource = RCC_SYSCLKSOURCE_PLLCLK;
  RCC_ClkInitStruct.AHBCLKDivider = RCC_SYSCLK_DIV1;
  RCC_ClkInitStruct.APB1CLKDivider = RCC_HCLK_DIV4;
  RCC_ClkInitStruct.APB2CLKDivider = RCC_HCLK_DIV2;

  if (HAL_RCC_ClockConfig(&RCC_ClkInitStruct, FLASH_LATENCY_7) != HAL_OK)
  {
    Error_Handler();
  }
}

void HAL_TIM_PeriodElapsedCallback(TIM_HandleTypeDef *htim)
{
  if (htim->Instance == TIM6)
  {
    HAL_IncTick();
  }
}

void Error_Handler(void)
{
  __disable_irq();
  while (1)
  {
  }
}

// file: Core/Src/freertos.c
/* USER CODE BEGIN Header */
/**
  ******************************************************************************
  * File Name          : freertos.c
  * Description        : Code for freertos applications
  ******************************************************************************
  * PS2 Controller Task added for STM32F767ZI
  ******************************************************************************
  */
/* USER CODE END Header */

#include "FreeRTOS.h"
#include "task.h"
#include "main.h"
#include "cmsis_os.h"

/* USER CODE BEGIN Includes */
#include <stdint.h>
#ifdef ROBOT_MICROROS
#include "robot_microros.h"
#endif
/* USER CODE END Includes */

/* USER CODE BEGIN PD */

#define PS2_TASK_PERIOD_MS       10U
#define PS2_AXIS_CENTER          128U
#define PS2_VALID_FRAMES_TO_CONNECT       3U
#define PS2_RECONFIGURE_AFTER_INVALID   100U
/* USER CODE END PD */

osThreadId defaultTaskHandle;

/* USER CODE BEGIN Variables */

osThreadId ps2TaskHandle;

/* Trang thai PS2 duoc cap nhat boi PS2 Task */
volatile uint8_t g_ps2_connected = 0U;

volatile uint8_t g_ps2_lx = PS2_AXIS_CENTER;
volatile uint8_t g_ps2_ly = PS2_AXIS_CENTER;

volatile uint8_t g_ps2_l1_pressed = 0U;

/* USER CODE END Variables */

/* USER CODE BEGIN FunctionPrototypes */
extern void PS2_ReconfigureAnalog(void);
extern void Robot_MotorControl_Update(
    uint8_t ps2_connected,
    uint8_t lx,
    uint8_t ly,
    uint8_t l1_pressed
);
extern uint8_t PS2_Init(void);

extern uint8_t PS2_ReadState(
    uint8_t *lx,
    uint8_t *ly,
    uint8_t *l1_pressed
);

void StartPS2Task(void const *argument);

/* USER CODE END FunctionPrototypes */

void StartDefaultTask(void const *argument);

extern void MX_USB_DEVICE_Init(void);
extern void MX_LWIP_Init(void);

void MX_FREERTOS_Init(void);

/* GetIdleTaskMemory prototype */
void vApplicationGetIdleTaskMemory(
    StaticTask_t **ppxIdleTaskTCBBuffer,
    StackType_t **ppxIdleTaskStackBuffer,
    uint32_t *pulIdleTaskStackSize
);

/* USER CODE BEGIN GET_IDLE_TASK_MEMORY */

static StaticTask_t xIdleTaskTCBBuffer;

static StackType_t xIdleStack[configMINIMAL_STACK_SIZE];

void vApplicationGetIdleTaskMemory(
    StaticTask_t **ppxIdleTaskTCBBuffer,
    StackType_t **ppxIdleTaskStackBuffer,
    uint32_t *pulIdleTaskStackSize)
{
    *ppxIdleTaskTCBBuffer = &xIdleTaskTCBBuffer;
    *ppxIdleTaskStackBuffer = &xIdleStack[0];
    *pulIdleTaskStackSize = configMINIMAL_STACK_SIZE;
}

/* USER CODE END GET_IDLE_TASK_MEMORY */

void MX_FREERTOS_Init(void)
{

    /* Create the thread(s) */

    /* Default Task */
    osThreadDef(
        defaultTask,
        StartDefaultTask,
        osPriorityNormal,
        0,
        256
    );

    defaultTaskHandle = osThreadCreate(
        osThread(defaultTask),
        NULL
    );

    /* USER CODE BEGIN RTOS_THREADS */

    /* PS2 Controller Task */
    osThreadDef(
        ps2Task,
        StartPS2Task,
        osPriorityNormal,
        0,
        256
    );

    ps2TaskHandle = osThreadCreate(
        osThread(ps2Task),
        NULL
    );

    /* USER CODE END RTOS_THREADS */
}

void StartDefaultTask(void const *argument)
{
    (void)argument;

    /* Initialize USB Device */
    MX_USB_DEVICE_Init();

    /* Initialize LWIP */
    MX_LWIP_Init();

    /* USER CODE BEGIN StartDefaultTask */
#ifdef ROBOT_MICROROS
    osThreadDef(microRosTask, Robot_MicroRosTask, osPriorityBelowNormal, 0, 4096);
    (void)osThreadCreate(osThread(microRosTask), NULL);
#endif

    for (;;)
    {
        osDelay(1U);
    }

    /* USER CODE END StartDefaultTask */
}

/* USER CODE BEGIN Application */

/**
  * @brief PS2 Controller Task
  *
  * Nhiem vu:
  * - Khoi tao PS2
  * - Doc joystick trai X/Y
  * - Doc nut L1
  * - Cap nhat trang thai ket noi
  *
  * Chu ky doc: 10 ms
  */

void StartPS2Task(void const *argument)
{
    uint8_t lx = PS2_AXIS_CENTER;
    uint8_t ly = PS2_AXIS_CENTER;
    uint8_t l1 = 0U;

    uint8_t valid_frames = 0U;
    uint16_t invalid_frames = 0U;

    (void)argument;

    /* ==========================================
     * 1. INITIALIZE PS2
     * ========================================== */

    for (;;)
    {
        if (PS2_Init() != 0U)
        {
            break;
        }

        g_ps2_connected = 0U;

        g_ps2_lx = PS2_AXIS_CENTER;
        g_ps2_ly = PS2_AXIS_CENTER;
        g_ps2_l1_pressed = 0U;

        Robot_MotorControl_Update(
            0U,
            PS2_AXIS_CENTER,
            PS2_AXIS_CENTER,
            0U
        );

        osDelay(500U);
    }

    /* ==========================================
     * 2. READ PS2 CONTINUOUSLY
     * ========================================== */

    for (;;)
    {
        if (PS2_ReadState(&lx, &ly, &l1) != 0U)
        {
            /* Valid frame */
            invalid_frames = 0U;

            if (valid_frames < PS2_VALID_FRAMES_TO_CONNECT)
            {
                valid_frames++;
            }

            if (valid_frames >= PS2_VALID_FRAMES_TO_CONNECT)
            {
                g_ps2_connected = 1U;

                g_ps2_lx = lx;
                g_ps2_ly = ly;
                g_ps2_l1_pressed = l1;
            }
            else
            {
                /* Wait for 3 consecutive valid frames */
                g_ps2_connected = 0U;

                g_ps2_lx = PS2_AXIS_CENTER;
                g_ps2_ly = PS2_AXIS_CENTER;
                g_ps2_l1_pressed = 0U;
            }
        }
        else
        {
            /* Invalid frame: stop motor immediately */
            valid_frames = 0U;

            g_ps2_connected = 0U;

            g_ps2_lx = PS2_AXIS_CENTER;
            g_ps2_ly = PS2_AXIS_CENTER;
            g_ps2_l1_pressed = 0U;

            if (invalid_frames < PS2_RECONFIGURE_AFTER_INVALID)
            {
                invalid_frames++;
            }

            /* Reconfigure after 1 second of continuous errors */
            if (invalid_frames >= PS2_RECONFIGURE_AFTER_INVALID)
            {
                PS2_ReconfigureAnalog();
                invalid_frames = 0U;
            }
        }

        /* Update motor control */
        Robot_MotorControl_Update(
            g_ps2_connected,
            g_ps2_lx,
            g_ps2_ly,
            g_ps2_l1_pressed
        );

        osDelay(PS2_TASK_PERIOD_MS);
    }
}

/* USER CODE END Application */
